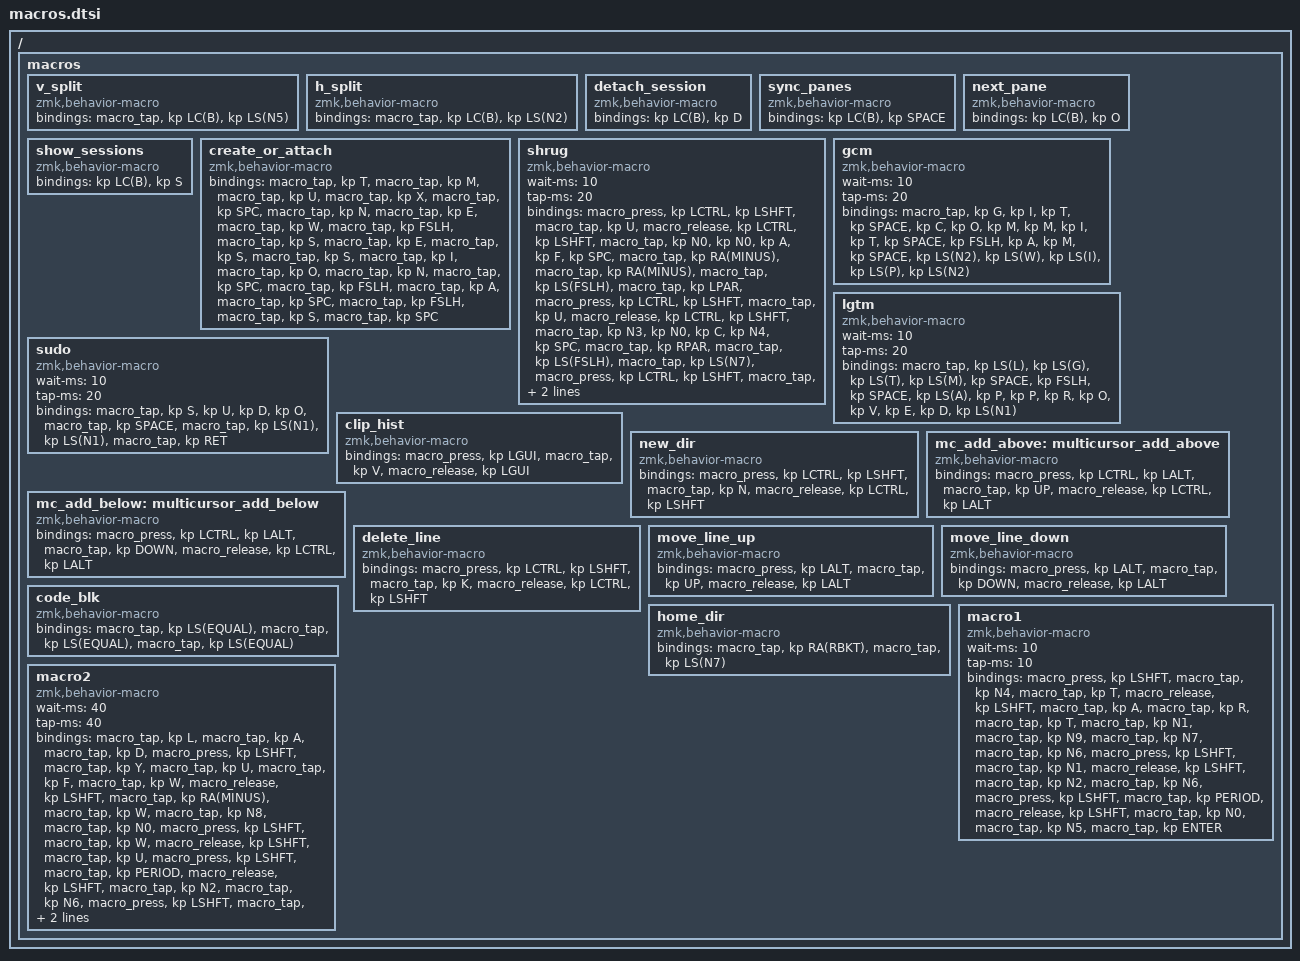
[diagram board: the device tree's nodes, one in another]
/ {
    macros {
        v_split: v_split {
            compatible = "zmk,behavior-macro";
            #binding-cells = <0>;
            bindings = <&macro_tap &kp LC(B) &kp LS(N5)>;
        };

        h_split: h_split {
            compatible = "zmk,behavior-macro";
            #binding-cells = <0>;
            bindings = <&macro_tap &kp LC(B) &kp LS(N2)>;
        };

        detach_session: detach_session {
            compatible = "zmk,behavior-macro";
            #binding-cells = <0>;
            bindings = <&kp LC(B) &kp D>;
        };

        sync_panes: sync_panes {
            compatible = "zmk,behavior-macro";
            #binding-cells = <0>;
            bindings = <&kp LC(B) &kp SPACE>;
        };

        next_pane: next_pane {
            compatible = "zmk,behavior-macro";
            #binding-cells = <0>;
            bindings = <&kp LC(B) &kp O>;
        };

        show_sessions: show_sessions {
            compatible = "zmk,behavior-macro";
            #binding-cells = <0>;
            bindings = <&kp LC(B) &kp S>;
        };

        create_or_attach: create_or_attach {
            compatible = "zmk,behavior-macro";
            #binding-cells = <0>;
            bindings
                = <&macro_tap &kp T>
                , <&macro_tap &kp M>
                , <&macro_tap &kp U>
                , <&macro_tap &kp X>
                , <&macro_tap &kp SPC>
                , <&macro_tap &kp N>
                , <&macro_tap &kp E>
                , <&macro_tap &kp W>
                , <&macro_tap &kp FSLH>
                , <&macro_tap &kp S>
                , <&macro_tap &kp E>
                , <&macro_tap &kp S>
                , <&macro_tap &kp S>
                , <&macro_tap &kp I>
                , <&macro_tap &kp O>
                , <&macro_tap &kp N>
                , <&macro_tap &kp SPC>
                , <&macro_tap &kp FSLH>
                , <&macro_tap &kp A>
                , <&macro_tap &kp SPC>
                , <&macro_tap &kp FSLH>
                , <&macro_tap &kp S>
                , <&macro_tap &kp SPC>
            ;
        };

        shrug: shrug { // shrug emoji ¯\_(ツ)_/¯
            compatible = "zmk,behavior-macro";
            #binding-cells = <0>;
            wait-ms = <10>;
            tap-ms = <20>;
            bindings
                // ¯ (Macros)
                = <&macro_press &kp LCTRL &kp LSHFT>
                , <&macro_tap &kp U>
                , <&macro_release &kp LCTRL &kp LSHFT>
                , <&macro_tap &kp N0 &kp N0 &kp A &kp F &kp SPC>
                // \
                , <&macro_tap &kp RA(MINUS)>
                , <&macro_tap &kp RA(MINUS)>
                // _
                , <&macro_tap &kp LS(FSLH)>
                // (
                , <&macro_tap &kp LPAR>
                // ツ (Katakana Letter Tu)
                , <&macro_press &kp LCTRL &kp LSHFT>
                , <&macro_tap &kp U>
                , <&macro_release &kp LCTRL &kp LSHFT>
                , <&macro_tap &kp N3 &kp N0 &kp C &kp N4 &kp SPC>
                // )
                , <&macro_tap &kp RPAR>
                // _
                , <&macro_tap &kp LS(FSLH)>
                // /
                , <&macro_tap &kp LS(N7)>
                // ¯ (Macron)
                , <&macro_press &kp LCTRL &kp LSHFT>
                , <&macro_tap &kp U>
                , <&macro_release &kp LCTRL &kp LSHFT>
                , <&macro_tap &kp N0 &kp N0 &kp A &kp F &kp SPC>
                ;
        };

        gcm: gcm { // git commit WIP
            compatible = "zmk,behavior-macro";
            #binding-cells = <0>;
            wait-ms = <10>;
            tap-ms = <20>;
            bindings = <
                &macro_tap &kp G &kp I &kp T &kp SPACE
                &kp C &kp O &kp M &kp M &kp I &kp T &kp SPACE
                &kp FSLH &kp A &kp M &kp SPACE
                &kp LS(N2) &kp LS(W) &kp LS(I) &kp LS(P) &kp LS(N2)
            >;
        };

        lgtm: lgtm { // LGTM Approval
            compatible = "zmk,behavior-macro";
            #binding-cells = <0>;
            wait-ms = <10>;
            tap-ms = <20>;
            bindings = <
                &macro_tap
                &kp LS(L) &kp LS(G) &kp LS(T) &kp LS(M)
                &kp SPACE &kp FSLH &kp SPACE
                &kp LS(A) &kp P &kp P &kp R &kp O &kp V &kp E &kp D &kp LS(N1)
            >;
        };

        sudo: sudo { // SUDO_BANG_BANG
            compatible = "zmk,behavior-macro";
            #binding-cells = <0>;
            wait-ms = <10>;
            tap-ms = <20>;
            bindings
                = <&macro_tap &kp S &kp U &kp D &kp O>  // "sudo"
                , <&macro_tap &kp SPACE>                // space
                , <&macro_tap &kp LS(N1) &kp LS(N1)>    // "!!"
                , <&macro_tap &kp RET>                  // Enter key
                ;
        };
        
        clip_hist: clip_hist { // CLIPBOARD_HISTORY
            compatible = "zmk,behavior-macro";
            #binding-cells = <0>;
            bindings 
                = <&macro_press &kp LGUI>
                , <&macro_tap &kp V>
                , <&macro_release &kp LGUI>
                ;
        };
        
        new_dir: new_dir {
            compatible = "zmk,behavior-macro";
            #binding-cells = <0>;
            bindings
                = <&macro_press &kp LCTRL &kp LSHFT>
                , <&macro_tap &kp N>
                , <&macro_release &kp LCTRL &kp LSHFT>
                ;
        };

        mc_add_above: multicursor_add_above {
            compatible = "zmk,behavior-macro";
            #binding-cells = <0>;
            bindings
                = <&macro_press &kp LCTRL &kp LALT>
                , <&macro_tap &kp UP>
                , <&macro_release &kp LCTRL &kp LALT>
                ;
        };

        mc_add_below: multicursor_add_below {
            compatible = "zmk,behavior-macro";
            #binding-cells = <0>;
            bindings
                = <&macro_press &kp LCTRL &kp LALT>
                , <&macro_tap &kp DOWN>
                , <&macro_release &kp LCTRL &kp LALT>
                ;
        };

        delete_line: delete_line {
            compatible = "zmk,behavior-macro";
            #binding-cells = <0>;
            bindings
                = <&macro_press &kp LCTRL &kp LSHFT>
                , <&macro_tap &kp K>
                , <&macro_release &kp LCTRL &kp LSHFT>
                ;
        };

        move_line_up: move_line_up {
            compatible = "zmk,behavior-macro";
            #binding-cells = <0>;
            bindings
                = <&macro_press &kp LALT>
                , <&macro_tap &kp UP>
                , <&macro_release &kp LALT>
                ;
        };

        move_line_down: move_line_down {
            compatible = "zmk,behavior-macro";
            #binding-cells = <0>;
            bindings
                = <&macro_press &kp LALT>
                , <&macro_tap &kp DOWN>
                , <&macro_release &kp LALT>
                ;
        };

        code_blk: code_blk {
            compatible = "zmk,behavior-macro";
            #binding-cells = <0>;
            bindings
                = <&macro_tap &kp LS(EQUAL)>
                , <&macro_tap &kp LS(EQUAL)>
                , <&macro_tap &kp LS(EQUAL)>
                ;
        };
        
        home_dir: home_dir {
            compatible = "zmk,behavior-macro";
            #binding-cells = <0>;
            bindings
                = <&macro_tap &kp RA(RBKT)>
                , <&macro_tap &kp LS(N7)>
                ;
        };

        macro1: macro1 {
            compatible = "zmk,behavior-macro";
            #binding-cells = <0>;

            // bisschen mehr Luft für Citrix
            wait-ms = <10>;
            tap-ms  = <10>;

            bindings
                // "$" = Shift + N4  (statt &kp DLLR)
                = <&macro_press &kp LSHFT>
                , <&macro_tap &kp N4>
                , <&macro_tap &kp T>      // T
                , <&macro_release &kp LSHFT>
                , <&macro_tap &kp A>
                , <&macro_tap &kp R>
                , <&macro_tap &kp T>
                , <&macro_tap &kp N1>
                , <&macro_tap &kp N9>
                , <&macro_tap &kp N7>
                , <&macro_tap &kp N6>
                , <&macro_press &kp LSHFT>
                , <&macro_tap &kp N1>
                , <&macro_release &kp LSHFT>
                , <&macro_tap &kp N2>
                , <&macro_tap &kp N6>
                , <&macro_press &kp LSHFT>
                , <&macro_tap &kp PERIOD>
                , <&macro_release &kp LSHFT>
                , <&macro_tap &kp N0>
                , <&macro_tap &kp N5>
                , <&macro_tap &kp ENTER>
                ;
        };


        macro2: macro2 { // types ladZUFW\w80Wu:25:10
            compatible = "zmk,behavior-macro";
            #binding-cells = <0>;

            // etwas träger für Citrix
            wait-ms = <40>;
            tap-ms  = <40>;

            bindings
                = <&macro_tap &kp L>       // l
                , <&macro_tap &kp A>       // a
                , <&macro_tap &kp D>       // d

                // "ZUFW" groß
                , <&macro_press &kp LSHFT>
                , <&macro_tap &kp Y>       // Z
                , <&macro_tap &kp U>       // U
                , <&macro_tap &kp F>       // F
                , <&macro_tap &kp W>       // W
                , <&macro_release &kp LSHFT>

                , <&macro_tap &kp RA(MINUS)>    // \
                , <&macro_tap &kp W>       // W
                , <&macro_tap &kp N8>      // 8
                , <&macro_tap &kp N0>      // 0

                // "W" groß
                , <&macro_press &kp LSHFT>
                , <&macro_tap &kp W>       // W
                , <&macro_release &kp LSHFT>

                , <&macro_tap &kp U>       // u

                // ":"  -> Shift + PERIOD (DE)
                , <&macro_press &kp LSHFT>
                , <&macro_tap &kp PERIOD>
                , <&macro_release &kp LSHFT>

                , <&macro_tap &kp N2>
                , <&macro_tap &kp N6>

                // zweites ":" -> wieder Shift + PERIOD
                , <&macro_press &kp LSHFT>
                , <&macro_tap &kp PERIOD>
                , <&macro_release &kp LSHFT>

                , <&macro_tap &kp N0>
                , <&macro_tap &kp N1>
                ;
        };


    };
};
